VERSION ""

NS_ :

BS_: 250000

BU_: PCM BCM All_ECUs HMI

BO_ 128 PCM_BuzzerCmd: 1 HMI
 SG_ BuzzerMode : 0|8@1+ (1,0) [0|3] "" HMI

BO_ 129 PCM_LEDStateCmd: 1 HMI
 SG_ LED_State : 0|8@1+ (1,0) [0|3] "" HMI

BO_ 256 BCM_FanTarget: 1 HMI
 SG_ FanTargetSpeed : 0|8@1+ (1,0) [0|100] "%" HMI

BO_ 257 BCM_WindowTarget: 1 HMI
 SG_ WindowTargetPos : 0|8@1+ (1,0) [0|100] "%" HMI

BO_ 258 BCM_BuzzerCmd: 1 HMI
 SG_ BuzzerMode : 0|8@1+ (1,0) [0|3] "" HMI

BO_ 259 BCM_LEDStateCmd: 1 HMI
 SG_ LED_State : 0|8@1+ (1,0) [0|3] "" HMI

BO_ 384 PCM_ParkingDistance: 3 PCM
 SG_ UltrasonicFlags : 0|8@1+ (1,0) [0|255] "" HMI
 SG_ ParkingDistance : 8|16@1+ (1,0) [0|400] "cm" HMI

BO_ 385 PCM_GearPosition: 2 PCM
 SG_ GearFlags : 0|8@1+ (1,0) [0|255] "" HMI
 SG_ GearPosition : 8|8@1+ (1,0) [0|2] "" HMI

BO_ 386 PCM_FuelLevel: 3 PCM
 SG_ FuelFlags : 0|8@1+ (1,0) [0|255] "" HMI
 SG_ FuelLevel : 8|16@1+ (0.1,0) [0|1000] "%" HMI

BO_ 387 PCM_EngineSpeed: 3 PCM
 SG_ RPM_Flags : 0|8@1+ (1,0) [0|255] "" HMI
 SG_ EngineSpeed : 8|16@1+ (0.1,0) [0|1000] "%" HMI

BO_ 512 BCM_CabinTemperature: 3 BCM
 SG_ TempFlags : 0|8@1+ (1,0) [0|255] "" HMI
 SG_ CabinTemperature : 8|16@1+ (0.1,0) [-400|850] "degC" HMI

BO_ 513 BCM_CabinHumidity: 3 BCM
 SG_ HumidFlags : 0|8@1+ (1,0) [0|255] "" HMI
 SG_ CabinHumidity : 8|16@1+ (0.1,0) [0|1000] "%" HMI

BO_ 514 BCM_FanActualSpeed: 2 BCM
 SG_ FanFlags : 0|8@1+ (1,0) [0|255] "" HMI
 SG_ FanActualSpeed : 8|8@1+ (1,0) [0|100] "%" HMI

BO_ 515 BCM_WindowActualPos: 2 BCM
 SG_ WindowFlags : 0|8@1+ (1,0) [0|255] "" HMI
 SG_ WindowActualPos : 8|8@1+ (1,0) [0|100] "%" HMI

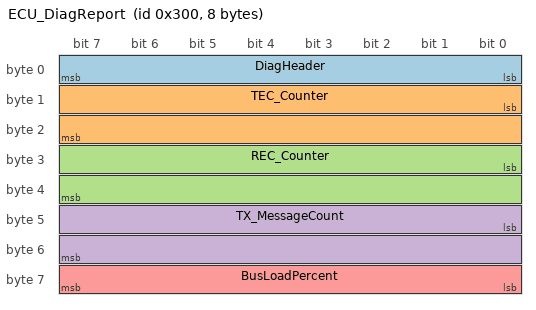
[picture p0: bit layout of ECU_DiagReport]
BO_ 768 ECU_DiagReport: 8 All_ECUs
 SG_ DiagHeader : 0|8@1+ (1,0) [0|255] "" HMI
 SG_ TEC_Counter : 8|16@1+ (1,0) [0|255] "" HMI
 SG_ REC_Counter : 24|16@1+ (1,0) [0|255] "" HMI
 SG_ TX_MessageCount : 40|16@1+ (1,0) [0|65535] "" HMI
 SG_ BusLoadPercent : 56|8@1+ (1,0) [0|100] "%" HMI

CM_ BO_ 128 "PCM_BuzzerCmd";
CM_ BO_ 129 "PCM_LEDStateCmd";
CM_ BO_ 256 "BCM_FanTarget";
CM_ BO_ 257 "BCM_WindowTarget";
CM_ BO_ 258 "BCM_BuzzerCmd";
CM_ BO_ 259 "BCM_LEDStateCmd";
CM_ BO_ 384 "PCM_ParkingDistance";
CM_ BO_ 385 "PCM_GearPosition";
CM_ BO_ 386 "PCM_FuelLevel";
CM_ BO_ 387 "PCM_EngineSpeed";
CM_ BO_ 512 "BCM_CabinTemperature";
CM_ BO_ 513 "BCM_CabinHumidity";
CM_ BO_ 514 "BCM_FanActualSpeed";
CM_ BO_ 515 "BCM_WindowActualPos";
CM_ BO_ 768 "ECU_DiagReport";
VAL_ 385 GearPosition 0 "P" 1 "R" 2 "D" ;
VAL_ 128 BuzzerMode 0 "OFF" 3 "ALERT" ;
VAL_ 258 BuzzerMode 0 "OFF" 3 "ALERT" ;
VAL_ 129 LED_State 0 "OFF" 3 "ALERT" ;
VAL_ 259 LED_State 0 "OFF" 3 "ALERT" ;
VAL_ 768 DiagHeader 0 "OK" 16 "Warning" 32 "ErrorPassive" 48 "BusOff" ;
